# FM33L0XXD register map
File version: 1.0
CPU: SC000 r1p0, little endian, no MPU, FPU, 8 interrupt priority bits
Registers are 32-bit, read-write, reset 0x0 unless marked. A register's access mark holds for its fields unless they carry their own. Offsets are from the block's base; [hi:lo] are bit positions; {n}, {i} and the like mark numbered series.

## GPIOAHD — GPIOAHD module information
Base 0x40000F00
Same registers: GPIOBHD 0x40000F10, GPIOCHD 0x40000F20, GPIODHD 0x40000F30, GPIOEHD 0x40000F40, GPIOFHD 0x40000F50, GPIOGHD 0x40000F60
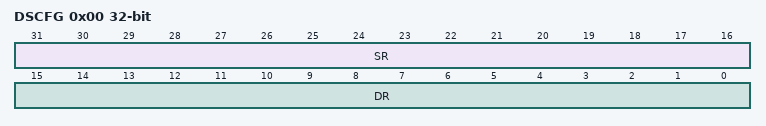
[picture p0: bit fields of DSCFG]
0x00 DSCFG
  [31:16] SR — SR field description
  [15:0] DR — DR field description
0x04 DFS
  [15:0] DFS — DFS field description
0x08 PDEN
  [15:0] PDEN — PDEN field description

## GPTIM0 — GPTIM0 module information
Base 0x40014400
Same registers: GPTIM1 0x40014800
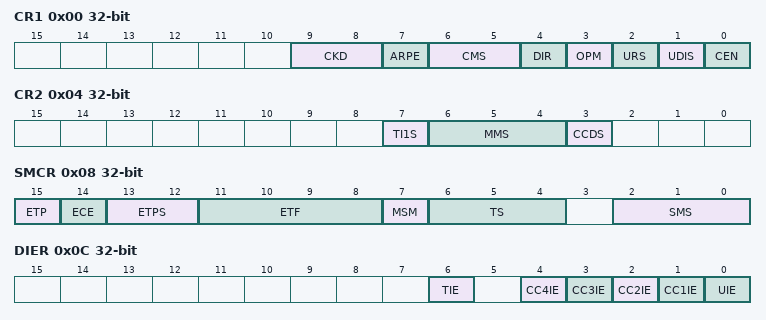
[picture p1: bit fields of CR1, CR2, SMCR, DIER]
0x00 CR1
  [9:8] CKD — CKD field description
  [7] ARPE — ARPE field description
  [6:5] CMS — CMS field description
  [4] DIR — DIR field description
  [3] OPM — OPM field description
  [2] URS — URS field description
  [1] UDIS — UDIS field description
  [0] CEN — CEN field description
0x04 CR2
  [7] TI1S — TI1S field description
  [6:4] MMS — MMS field description
  [3] CCDS — CCDS field description
0x08 SMCR
  [15] ETP — ETP field description
  [14] ECE — ECE field description
  [13:12] ETPS — ETPS field description
  [11:8] ETF — ETF field description
  [7] MSM — MSM field description
  [6:4] TS — TS field description
  [2:0] SMS — SMS field description
0x0C DIER
  [6] TIE — TIE field description
  [n] CC{n}IE (n=1..4) — CC{n}IE field description
  [0] UIE — UIE field description
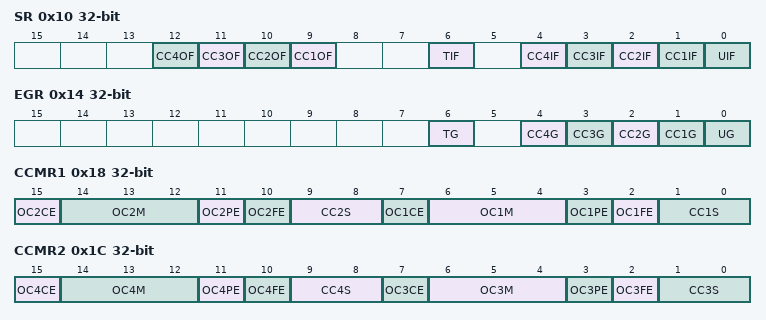
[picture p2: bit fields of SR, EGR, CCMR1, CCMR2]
0x10 SR
  [n+8] CC{n}OF (n=1..4) — CC{n}OF field description
  [6] TIF — TIF field description
  [n] CC{n}IF (n=1..4) — CC{n}IF field description
  [0] UIF — UIF field description
0x14 EGR
  [6] TG — TG field description
  [n] CC{n}G (n=1..4) — CC{n}G field description
  [0] UG — UG field description
0x18 CCMR1
  [15] OC2CE — OC2CE field description
  [14:12] OC2M — OC2M field description
  [11] OC2PE — OC2PE field description
  [10] OC2FE — OC2FE field description
  [9:8] CC2S — CC2S field description
  [7] OC1CE — OC1CE field description
  [6:4] OC1M — OC1M field description
  [3] OC1PE — OC1PE field description
  [2] OC1FE — OC1FE field description
  [1:0] CC1S — CC1S field description
0x1C CCMR2
  [15] OC4CE — OC4CE field description
  [14:12] OC4M — OC4M field description
  [11] OC4PE — OC4PE field description
  [10] OC4FE — OC4FE field description
  [9:8] CC4S — CC4S field description
  [7] OC3CE — OC3CE field description
  [6:4] OC3M — OC3M field description
  [3] OC3PE — OC3PE field description
  [2] OC3FE — OC3FE field description
  [1:0] CC3S — CC3S field description
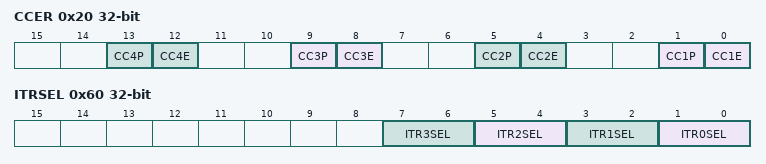
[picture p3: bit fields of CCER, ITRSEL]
0x20 CCER
  [4n-3] CC{n}P (n=1..4) — CC{n}P field description
  [4n-4] CC{n}E (n=1..4) — CC{n}E field description
0x24 CNT
  [15:0] CNT — CNT field description
0x28 PSC
  [15:0] PSC — PSC field description
0x2C ARR
  [15:0] ARR — ARR field description
{0x30+4i} CCR{i} (i=1..4)
  [15:0] CCR{i} — CCR{i} field description
0x60 ITRSEL
  [2n+1:2n] ITR{n}SEL (n=0..3) — ITR{n}SEL field description

## I2C0 — I2C0 module information
Base 0x40012400
Same registers: I2C1 0x40014000
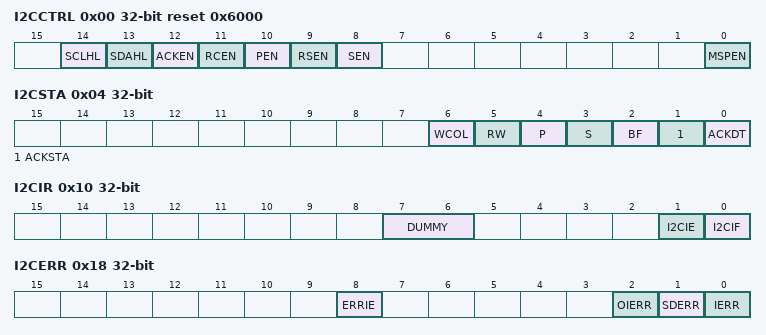
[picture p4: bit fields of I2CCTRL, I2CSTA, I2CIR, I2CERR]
0x00 I2CCTRL reset 0x6000
  [14] SCLHL — SCLHL field description
  [13] SDAHL — SDAHL field description
  [12] ACKEN — ACKEN field description
  [11] RCEN — RCEN field description
  [10] PEN — PEN field description
  [9] RSEN — RSEN field description
  [8] SEN — SEN field description
  [0] MSPEN — MSPEN field description
0x04 I2CSTA
  [6] WCOL — WCOL field description
  [5] RW ro — RW field description
  [4] P ro — P field description
  [3] S ro — S field description
  [2] BF ro — BF field description
  [1] ACKSTA — ACKSTA field description
  [0] ACKDT — ACKDT field description
0x08 I2CBRG reset 0x13
  [8:0] SSPBRG — SSPBRG field description
0x0C I2CBUF
  [7:0] SSPBUF — SSPBUF field description
0x10 I2CIR
  [7:6] DUMMY — DUMMY field description
  [1] I2CIE — I2CIE field description
  [0] I2CIF — I2CIF field description
0x18 I2CERR
  [8] ERRIE — ERRIE field description
  [2] OIERR — OIERR field description
  [1] SDERR — SDERR field description
  [0] IERR — IERR field description
